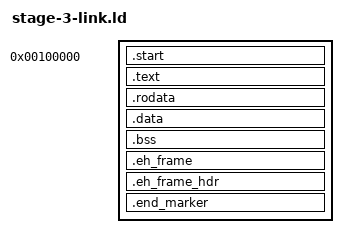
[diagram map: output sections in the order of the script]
ENTRY(_start)

SECTIONS {
    . = 0x00100000;

    .start : {
        *(.start)
    }
    .text : {
        *(.text .text.*)
    }
    .rodata : {
        *(.rodata .rodata.*)
    }
    .data : {
        *(.data .data.*)
    }
    .bss : {
        *(.bss .bss.*)
    }
    .eh_frame : {
        *(.eh_frame .eh_frame.*)
    }
    .eh_frame_hdr : {
        *(.eh_frame_hdr .eh_frame_hdr.*)
    }

    . = ALIGN(512);

    _third_stage_end = .;

    .end_marker :
    {
        SHORT(0xdead)
    }
}
